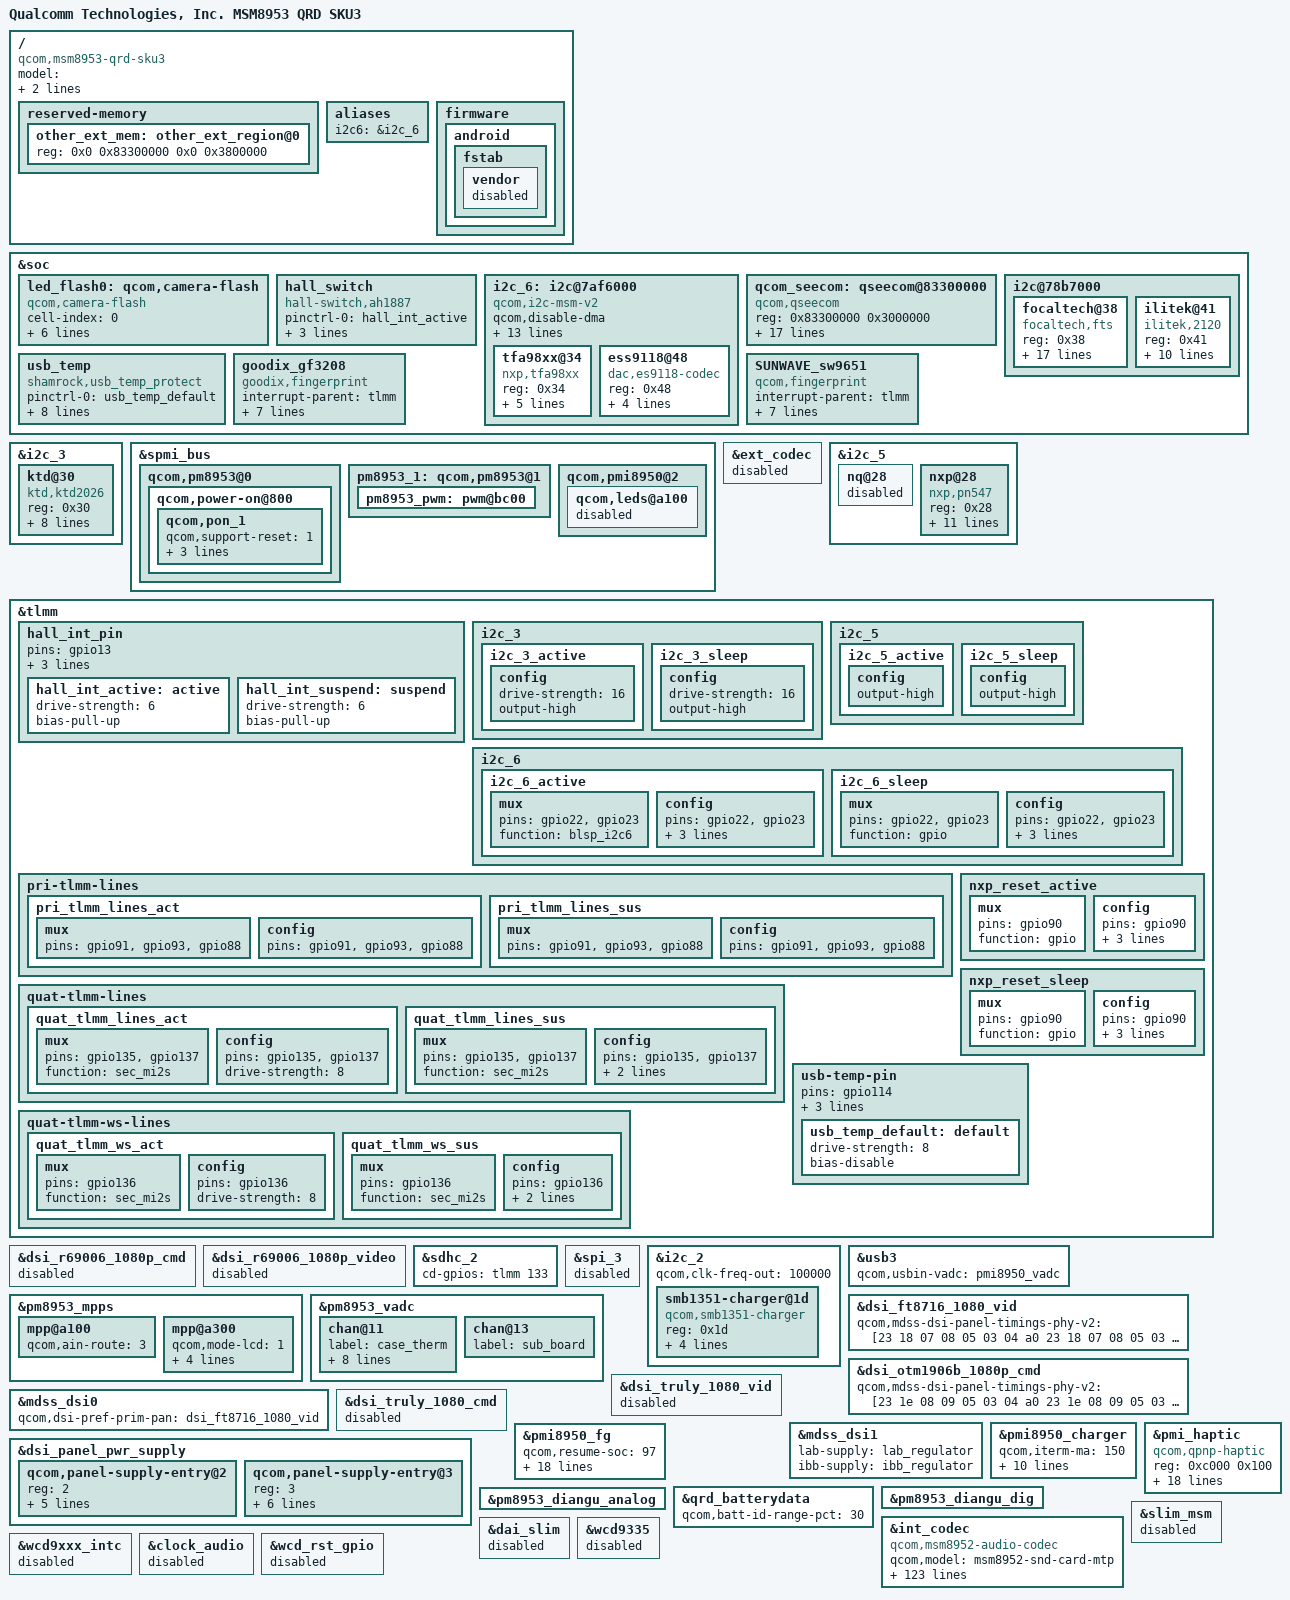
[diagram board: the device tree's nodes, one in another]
/*
 * Copyright (c) 2017, BQ. All rights reserved.
 *
 * This program is free software; you can redistribute it and/or modify
 * it under the terms of the GNU General Public License version 2 and
 * only version 2 as published by the Free Software Foundation.
 *
 * This program is distributed in the hope that it will be useful,
 * but WITHOUT ANY WARRANTY; without even the implied warranty of
 * MERCHANTABILITY or FITNESS FOR A PARTICULAR PURPOSE.  See the
 * GNU General Public License for more details.
 */

/dts-v1/;

#include "msm8953.dtsi"
#include "msm-pmi8950.dtsi"

#include "dsi-panel-ft8716-1080p-video.dtsi"
#include "dsi-panel-otm1906b-1080p-cmd.dtsi"

/ {
	model = "Qualcomm Technologies, Inc. MSM8953 QRD SKU3";
	compatible = "qcom,msm8953-qrd-sku3",
		   "qcom,msm8953-qrd", "qcom,msm8953", "qcom,qrd";
	qcom,board-id= <0x2000b 0>;
};

&soc {
	led_flash0: qcom,camera-flash {
		cell-index = <0>;
		compatible = "qcom,camera-flash";
		qcom,flash-type = <1>;
		qcom,flash-source = <&pmi8950_flash0 &pmi8950_flash1>;
		qcom,torch-source = <&pmi8950_torch0 &pmi8950_torch1>;
		qcom,switch-source = <&pmi8950_switch>;
	};
};

&i2c_3 { /* BLSP1 QUP3 */
    ktd@30 { /* Breath Light-Driven */
        compatible = "ktd,ktd2026";
        reg = <0x30>;
        vdd-supply = <&pm8953_l10>;
        vcc_i2c-supply = <&pm8953_l6>;
        ktd,ledr-parameter_array = <255 12 500 12 500 0 0>;
        ktd,ledg-parameter_array = <255 12 500 12 500 0 0>;
        ktd,ledb-parameter_array = <255 12 500 12 500 0 0>;
    };
};

#include "msm8953-qrd-sku3.dtsi"
#include "bardock-camera.dtsi"

/ {
	reserved-memory {
		other_ext_mem: other_ext_region@0 {
			reg = <0x0 0x83300000 0x0 0x3800000>;
		};
	};

	aliases {
		i2c6  = &i2c_6;
	};
	firmware: firmware {
		android {
			fstab {
				vendor {
					status = "disabled";
				};
			};
		};
	};
};

&spmi_bus {
	qcom,pm8953@0 {
		qcom,power-on@800 {
			qcom,pon_1 {
				qcom,support-reset = <1>;
				qcom,s1-timer = <10256>;
				qcom,s2-timer = <2000>;
				qcom,s2-type = <8>;
			};
		};
	};
	pm8953_1: qcom,pm8953@1 {
		pm8953_pwm: pwm@bc00 {
			status = "okay";
		};
	};
};

&ext_codec {
	status = "disabled";
};

&i2c_5 { /* BLSP2 QUP1 (NFC) */
	nq@28 {
		status = "disabled";
	};
	
    nxp@28 {
            compatible = "nxp,pn547";
            reg = <0x28>;
            qcom,nxp-irq = <&tlmm 17 0x00>;
            qcom,nxp-ven = <&tlmm 16 0x00>;
            qcom,nxp-dw-req = <&tlmm 62 0x00>;
            qcom,nxp-clkreq = <&pm8953_gpios 2 0x00>;
            interrupt-parent = <&tlmm>;
            qcom,clk-src = "BBCLK2";
            interrupts = <17 0>;
            interrupt-names = "nxp-irq";
            pinctrl-names = "nfc_active", "nfc_suspend";
            pinctrl-0 = <&nfc_int_active &nfc_disable_active>;
            pinctrl-1 = <&nfc_int_suspend &nfc_disable_suspend>;
            clocks = <&clock_gcc clk_bb_clk2_pin>;
            clock-names = "ref_clk";
    };
};

&tlmm {
	hall_int_pin {
		pins = "gpio13";
		qcom,pin-func = <0>;
		qcom,num-grp-pins = <1>;
		label = "hall_int_pin";
		hall_int_active: active {
		        drive-strength = <6>;
		        bias-pull-up;
		};
		hall_int_suspend: suspend {
		        drive-strength = <6>;
		        bias-pull-up;
		};
	};

	i2c_3 {
		i2c_3_active: i2c_3_active {
			config {
				drive-strength = <16>;
				output-high;
			};
		};
		i2c_3_sleep: i2c_3_sleep {
			config {
				drive-strength = <16>;
				output-high;
			};
		};
	};

	i2c_5 {
		i2c_5_active: i2c_5_active {
			config {
				output-high;
			};
		};
		i2c_5_sleep: i2c_5_sleep {
			config {
				output-high;
			};
		};
	};

	i2c_6 {
		i2c_6_active: i2c_6_active {
			/* active state */
			mux {
				pins = "gpio22", "gpio23";
				function = "blsp_i2c6";
			};

			config {
				pins = "gpio22", "gpio23";
				drive-strength = <2>;
				bias-disable;
				output-high;
			};
		};

		i2c_6_sleep: i2c_6_sleep {
			/* suspended state */
			mux {
				pins = "gpio22", "gpio23";
				function = "gpio";
			};

			config {
				pins = "gpio22", "gpio23";
				drive-strength = <2>;
				bias-disable;
				output-high;
			};
		};
	};

	pri-tlmm-lines {
		pri_tlmm_lines_act: pri_tlmm_lines_act {
			mux {
				pins = "gpio91", "gpio93", "gpio88";
			};
			config {
				pins = "gpio91", "gpio93", "gpio88";
			};
		};
		pri_tlmm_lines_sus: pri_tlmm_lines_sus {
			mux {
				pins = "gpio91", "gpio93", "gpio88";
			};
			config {
				pins = "gpio91", "gpio93", "gpio88";
			};
		};
	};

	quat-tlmm-lines {
		quat_tlmm_lines_act: quat_tlmm_lines_act {
			mux {
				pins = "gpio135", "gpio137";
				function = "sec_mi2s";
			};

			config {
				pins = "gpio135", "gpio137";
				drive-strength = <8>;
			};
		};

		quat_tlmm_lines_sus: quat_tlmm_lines_sus {
			mux {
				pins = "gpio135", "gpio137";
				function = "sec_mi2s";
			};

			config {
				pins = "gpio135", "gpio137";
				drive-strength = <2>;
				bias-pull-down;
			};
		};
	};

	quat-tlmm-ws-lines {
		quat_tlmm_ws_act: quat_tlmm_ws_act {
			mux {
				pins = "gpio136";
				function = "sec_mi2s";
			};

			config {
				pins = "gpio136";
				drive-strength = <8>;
			};
		};

		quat_tlmm_ws_sus: quat_tlmm_ws_sus {
			mux {
				pins = "gpio136";
				function = "sec_mi2s";
			};

			config {
				pins = "gpio136";
				drive-strength = <2>;
				bias-pull-down;
			};
		};
	};

	nxp_reset_active: nxp_reset_active {
		mux {
			pins = "gpio90";
			function =  "gpio";
		};
		config {
			pins = "gpio90";
			num-grp-pins = <1>;
			drive-strength = <6>;
			bias-pull-up;
		};
	};

	nxp_reset_sleep: nxp_reset_sleep {
			mux {
				pins = "gpio90";
				function =  "gpio";
			};
			config {
				pins = "gpio90";
				num-grp-pins = <1>;
				drive-strength = <2>;
				bias-disable;
			};
	};

	usb-temp-pin {
		pins = "gpio114";
		qcom,num-grp-pins = <1>;
		qcom,pin-func = <0>;
		label = "usb-temp-pin";
		usb_temp_default: default {
			drive-strength = <8>;
			bias-disable;
		};
	};

};

&dsi_r69006_1080p_cmd {
	status = "disabled";
};

&dsi_r69006_1080p_video {
	status = "disabled";
};

&spmi_bus {
	qcom,pmi8950@2 {
		qcom,leds@a100 {
			status = "disabled";
		};
	};
};

&sdhc_2 {
	cd-gpios = <&tlmm 133 0x0>;
};

&spi_3 {
	status = "disabled";
};

&i2c_2 {
	qcom,clk-freq-out = <100000>;
};

&soc {
	hall_switch {
		compatible = "hall-switch,ah1887";
		pinctrl-names = "hall_active","hall_suspend";
		pinctrl-0 = <&hall_int_active>;
		pinctrl-1 = <&hall_int_suspend>;
		vdd-io-supply = <&pm8953_l5>;
		interrupt-names = "hall_irq";
		hall,irq-gpio = <&tlmm 13 0x2008>;
	};

	i2c_6: i2c@7af6000 { /* BLSP2 QUP2 */
		compatible = "qcom,i2c-msm-v2";
		qcom,disable-dma;
		#address-cells = <1>;
		#size-cells = <0>;
		reg-names = "qup_phys_addr";
		reg = <0x7af6000 0x600>;
		interrupt-names = "qup_irq";
		interrupts = <0 300 0>;
		qcom,clk-freq-out = <400000>;
		qcom,clk-freq-in  = <19200000>;
		clock-names = "iface_clk", "core_clk";
		clocks = <&clock_gcc clk_gcc_blsp2_ahb_clk>,
			<&clock_gcc clk_gcc_blsp2_qup2_i2c_apps_clk>;
		pinctrl-names = "i2c_active", "i2c_sleep";
		pinctrl-0 = <&i2c_6_active>;
		pinctrl-1 = <&i2c_6_sleep>;
		qcom,noise-rjct-scl = <0>;
		qcom,noise-rjct-sda = <0>;
		qcom,master-id = <84>;
		dmas = <&dma_blsp2 6 64 0x20000020 0x20>,
			<&dma_blsp2 7 32 0x20000020 0x20>;
		dma-names = "tx", "rx";
	};

	/delete-node/ qseecom@85b00000;

	qcom_seecom: qseecom@83300000 {
		compatible = "qcom,qseecom";
		reg = <0x83300000 0x3000000>;
		reg-names = "secapp-region";
		qcom,hlos-num-ce-hw-instances = <1>;
		qcom,hlos-ce-hw-instance = <0>;
		qcom,qsee-ce-hw-instance = <0>;
		qcom,disk-encrypt-pipe-pair = <2>;
		qcom,support-fde;
		qcom,msm-bus,name = "qseecom-noc";
		qcom,msm-bus,num-cases = <4>;
		qcom,msm-bus,num-paths = <1>;
		qcom,support-bus-scaling;
		qcom,msm-bus,vectors-KBps =
			<55 512 0 0>,
			<55 512 0 0>,
			<55 512 120000 1200000>,
			<55 512 393600 3936000>;
		clocks = <&clock_gcc clk_crypto_clk_src>,
			 <&clock_gcc clk_gcc_crypto_clk>,
			 <&clock_gcc clk_gcc_crypto_ahb_clk>,
			 <&clock_gcc clk_gcc_crypto_axi_clk>;
		clock-names = "core_clk_src", "core_clk",
				"iface_clk", "bus_clk";
		qcom,ce-opp-freq = <100000000>;
	};

	i2c@78b7000 { /* BLSP1 QUP3 */
		status = "okay";
		focaltech@38{
			compatible = "focaltech,fts";
			reg = <0x38>;
			interrupt-parent = <&tlmm>;
			interrupts = <65 0x2>;
			/*vdd_ana-supply = <&vdd_vreg>;*/
			/*vdd-supply = <&pm8953_l10>;*/
			vcc_i2c-supply = <&pm8953_l6>;
			/* pins used by touchscreen */
			pinctrl-names = "pmx_ts_active","pmx_ts_suspend",
							"pmx_ts_release";
			pinctrl-0 = <&ts_int_active &ts_reset_active>;
			pinctrl-1 = <&ts_int_suspend &ts_reset_suspend>;
			pinctrl-2 = <&ts_release>;
			focaltech,name = "fts_ts";
			focaltech,family-id = <0x08>;
			focaltech,reset-gpio = <&tlmm 64 0x1>;
			focaltech,irq-gpio = <&tlmm 65 0x02>;
			focaltech,max-touch-number = <10>;
			focaltech,display-coords = <0 0 1080 1920>;
			focaltech,have-key;
			focaltech,key-number = <3>;
			focaltech,keys = <158 172 139>;
			focaltech,key-y-coord = <2000>;
			focaltech,key-x-coords = <200 600 800>;

		};
	};

	i2c@78b7000 { /* BLSP1 QUP3 */
		status = "ok";
		/*address-cells = <1>;*/
		/*size-cells = <0>;*/
		/*qcom,clk-freq-out = <400000>;*/
		ilitek@41{
			compatible = "ilitek,2120";
			reg = <0x41>;
			interrupt-parent = <&tlmm>;
			interrupts = <65 0x8>;
			ilitek,vci-gpio = <&tlmm 110 0x0>;
			vcc_i2c-supply = <&pm8953_l6>;
			vdd-supply = <&pm8953_l17>;
			ilitek,name = "ilitek_i2c";
			ilitek,reset-gpio = <&tlmm 64 0x00>;
			ilitek,irq-gpio = <&tlmm 65 0x00>;
			ilitek,vbus = "vcc_i2c";
			ilitek,vdd = "vdd";
		};
	};

	usb_temp {
		compatible = "shamrock,usb_temp_protect";
		pinctrl-names = "default";
		pinctrl-0 = <&usb_temp_default>;
		shamrock,gpio_usb_temp_protect = <&tlmm 114 0x00>;
		shamrock,need_protect_temp = <100>;
		shamrock,need_recover_temp = <85>;
		shamrock,open_mosfet_temp = <15>;
		shamrock,close_mosfet_temp = <10>;
		shamrock,interval_switch_temp = <7>;
		vdd-supply = <&pm8953_l6>;
		qcom,usb_temp-vadc = <&pm8953_vadc>;
		status = "okay";
	};

	goodix_gf3208 {
		compatible = "goodix,fingerprint";
		interrupt-parent = <&tlmm>;
		interrupts = <48 0x0>;

		vcc_spi-supply  = <&pm8953_l6>;
		vdd_ana-supply  = <&pm8953_l6>;
		vdd_io-supply   = <&pm8953_l6>;

		fp-gpio-reset = <&tlmm 140 0>;
		fp-gpio-irq = <&tlmm 48 0>;
		goodix,gpio_pwr = <&tlmm 35 0>;
	};

	SUNWAVE_sw9651 {
		compatible = "qcom,fingerprint";
		interrupt-parent = <&tlmm>;
		interrupts = <48 0x0>;

		vcc_spi-supply  = <&pm8953_l6>;
		vdd_ana-supply  = <&pm8953_l6>;
		vdd_io-supply   = <&pm8953_l6>;

		qcom,reset-gpio = <&tlmm 140 0>;
		qcom,irq-gpio = <&tlmm 48 0>;
		qcom,pwr-gpio = <&tlmm 35 0>;
	};
};

&usb3 {
	qcom,usbin-vadc = <&pmi8950_vadc>;
};

&pm8953_mpps {
	mpp@a100 {
		qcom,ain-route = <3>; /* AMUX 8 */
	};
	mpp@a300 {
		/* MPP4 - LCD_PWM config */
		qcom,mode-lcd = <1>; /* AIN input */
		qcom,invert-lcd = <0>;  /* Enable MPP */
		qcom,master-en-lcd = <1>;
		qcom,src-sel-lcd = <5>; /* Function constant */
		qcom,vin-sel-lcd = <2>;
	};
};

&pm8953_vadc {
	chan@11 {
		label = "case_therm";
		reg = <0x11>;
		qcom,decimation = <0>;
		qcom,pre-div-channel-scaling = <0>;
		qcom,calibration-type = "ratiometric";
		qcom,scale-function = <2>;
		qcom,hw-settle-time = <2>;
		qcom,fast-avg-setup = <0>;
		qcom,vadc-thermal-node;
	};
	chan@13 {
		label = "sub_board";
		status = "okay";
	};
};

&dsi_ft8716_1080_vid {
	qcom,mdss-dsi-panel-timings-phy-v2 = [23 18 07 08 05 03 04 a0
		23 18 07 08 05 03 04 a0
		23 18 07 08 05 03 04 a0
		23 18 07 08 05 03 04 a0
		23 1e 07 08 05 03 04 a0];
};

&dsi_otm1906b_1080p_cmd {
	qcom,mdss-dsi-panel-timings-phy-v2 = [23 1e 08 09 05 03 04 a0
		23 1e 08 09 05 03 04 a0
		23 1e 08 09 05 03 04 a0
		23 1e 08 09 05 03 04 a0
		23 1a 08 09 05 03 04 a0];
};

&mdss_dsi0 {
	qcom,dsi-pref-prim-pan = <&dsi_ft8716_1080_vid>;
};

&dsi_truly_1080_vid {
	status = "disabled";
};

&dsi_truly_1080_cmd {
	status = "disabled";
};

&mdss_dsi1 {
	lab-supply = <&lab_regulator>;
	ibb-supply = <&ibb_regulator>;
};

&dsi_panel_pwr_supply {
	qcom,panel-supply-entry@2 {
		reg = <2>;
		qcom,supply-name = "lab";
		qcom,supply-min-voltage = <4600000>;
		qcom,supply-max-voltage = <6000000>;
		qcom,supply-enable-load = <100000>;
		qcom,supply-disable-load = <100>;
	};

	qcom,panel-supply-entry@3 {
		reg = <3>;
		qcom,supply-name = "ibb";
		qcom,supply-min-voltage = <4600000>;
		qcom,supply-max-voltage = <6000000>;
		qcom,supply-enable-load = <100000>;
		qcom,supply-disable-load = <100>;
		qcom,supply-post-on-sleep = <10>;
	};
};

&pmi8950_charger {
	qcom,iterm-ma = <150>;
	qcom,float-voltage-mv = <4400>;
	qcom,resume-delta-mv = <100>;
	qcom,thermal-mitigation = <3000 2500 1950 1400 900 700 0>;
	qcom,fastchg-current-ma = <2200>;
	qcom,charging-timeout-mins = <768>;
	qcom,fastchg-current-comp = <1200>;
	/* 11 for 4.2V, 16 for 4.1V */
	qcom,float-voltage-comp = <16>;
	qcom,report-temp-by-d-work;
	qcom,override-usb-current;
};

&pmi8950_fg {
	qcom,resume-soc = <97>;
	qcom,fg-iterm-ma = <180>;
	qcom,fg-chg-iterm-ma = <150>;
	qcom,fg-cutoff-voltage-mv = <3400>;
	qcom,fg-cc-cv-threshold-mv = <4390>;
	qcom,cycle-counter-low-soc = <15>;
	qcom,cycle-counter-high-soc = <85>;
	qcom,cl-max-temp-decidegc = <450>;
	qcom,cl-min-temp-decidegc = <150>;
	qcom,cl-max-start-soc = <5>;
	qcom,capacity-learning-feedback;
	qcom,cold-bat-decidegc = <0>;
	qcom,cool-bat-decidegc = <150>;
	qcom,warm-bat-decidegc = <450>;
	qcom,fg-delta-soc = <1>;
	qcom,fg-vbat-estimate-diff-mv = <200>;
	qcom,fg-therm-delay-us = <3000>;
	qcom,cold-hot-jeita-hysteresis = <20 20>;
	qcom,ext-sense-type-mp;
};

&qrd_batterydata {
	qcom,batt-id-range-pct = <30>;
	#include "batterydata-qrd-jiade-4v4-3075mah.dtsi"
	#include "batterydata-qrd-feimaotui-4v4-3090mah.dtsi"
	/delete-node/ qcom,qrd_msm8937_sku1_2920mah;
};

&i2c_2 {
	//Parallel-charger configuration
	smb1351-charger@1d {
		compatible = "qcom,smb1351-charger";
		reg = <0x1d>;
		qcom,parallel-en-pin-polarity = <1>;
		qcom,parallel-charger;
		qcom,float-voltage-mv = <4400>;
		qcom,recharge-mv = <100>;
	};
};

&pmi_haptic {
	compatible = "qcom,qpnp-haptic";
	reg = <0xc000 0x100>;
	interrupts = <0x3 0xc0 0x0>,
		<0x3 0xc0 0x1>;
	interrupt-names = "sc-irq", "play-irq";
	qcom,play-mode = "buffer";
	qcom,wave-play-rate-us = <4255>;
	qcom,actuator-type = "lra";
	qcom,wave-shape = "sine";
	qcom,vmax-mv = <2000>;
	qcom,ilim-ma = <90>;
	qcom,sc-deb-cycles = <1>;
	qcom,int-pwm-freq-khz = <505>;
	qcom,brake-pattern = [00 00 00 00];
	qcom,use-play-irq;
	qcom,use-sc-irq;
	qcom,wave-samples = [7e 7e 7e 7e 7e 7e 7e];
	qcom,wave-rep-cnt = <1>;
	qcom,wave-samp-rep-cnt = <1>;
	qcom,lra-auto-res-mode = "none";
	qcom,lra-res-cal-period = <1>;
	qcom,correct-lra-drive-freq;
};

&i2c_6 {
	tfa98xx@34 {
		compatible = "nxp,tfa98xx";
		reg = <0x34>;
		nxp,tfa_max-vol-steps=<0x01>;
		nxp,reset-gpio = <&tlmm 89 0>;
		nxp,irq-gpio = <&tlmm 90 0x2008>;
		pinctrl-names = "nxp_reset_active","nxp_reset_suspend";
		pinctrl-0 = <&nxp_reset_active>;
		pinctrl-1 = <&nxp_reset_sleep>;
		status = "okay";
	};

	ess9118@48 {
		status = "okay";
		compatible = "dac,es9118-codec";
		reg = <0x48>;
		es9118,enable-gpio = <&tlmm 111 0>;
		es9118,power-gpio = <&tlmm 138 0>;
		es9118,cycle-gpio = <&tlmm 44 0>;
		es9118,reset-gpio = <&tlmm 120 0>;
	};
};

&pm8953_diangu_dig {
	status = "ok";
};

&pm8953_diangu_analog {
	status = "ok";
};

&int_codec {
	status = "ok";
	/delete-property/ qcom,cdc-us-euro-gpios;
	/delete-property/ asoc-wsa-codec-names;
	/delete-property/ asoc-wsa-codec-prefixes;
	compatible = "qcom,msm8952-audio-codec";
	qcom,model = "msm8952-snd-card-mtp";
	reg =	<0xc051000 0x4>,
		<0xc051004 0x4>,
		<0xc055000 0x4>,
		<0xc052000 0x4>,
		<0xc054000 0x4>;
	reg-names = "csr_gp_io_mux_mic_ctl",
		"csr_gp_io_mux_spkr_ctl",
		"csr_gp_io_lpaif_pri_pcm_pri_mode_muxsel",
		"csr_gp_io_mux_quin_ctl",
		"csr_gp_io_mux_mic_ext_clk_ctl";

	qcom,msm-hs-micbias-type = "external";//  internal
	qcom,msm-mbhc-hphl-swh = <1>;
	qcom,msm-mbhc-gnd-swh = <0>;   //0

	qcom,audio-routing =
		"RX_BIAS", "MCLK",
		"SPK_RX_BIAS", "MCLK",
		"INT_LDO_H", "MCLK",
		"MIC BIAS External", "Handset Mic",
		"MIC BIAS External2", "Headset Mic",
		"MIC BIAS External", "Secondary Mic",
		"AMIC1", "MIC BIAS External",
		"AMIC2", "MIC BIAS External2",
		"AMIC3", "MIC BIAS External";

	qcom,msm-ext-pa = "quinary","quaternary";
	qcom,msm-mclk-freq = <9600000>;
	qcom,msm-gpios =
		"pri_i2s",
		"us_eu_gpio",
		"quin_i2s",
		"quat_i2s";
	qcom,pinctrl-names =
		"all_off",
		"pri_i2s_act",
		"us_eu_gpio_act",
		"pri_i2s_us_eu_gpio_act",
		"quin_act",
		"quin_pri_i2s_act",
		"quin_us_eu_gpio_act",
		"quin_us_eu_gpio_pri_i2s_act",
		"quat_i2s_act",
		"quat_pri_i2s_act",
		"quat_us_eu_gpio_act",
		"quat_pri_i2s_us_eu_gpio_act",
		"quat_quin_act",
		"quat_quin_pri_i2s_act",
		"quat_quin_us_eu_gpio_act",
		"quat_quin_us_eu_gpio_pri_i2s_act";
	pinctrl-names =
		"all_off",
		"pri_i2s_act",
		"us_eu_gpio_act",
		"pri_i2s_us_eu_gpio_act",
		"quin_act",
		"quin_pri_i2s_act",
		"quin_us_eu_gpio_act",
		"quin_us_eu_gpio_pri_i2s_act",
		"quat_i2s_act",
		"quat_pri_i2s_act",
		"quat_us_eu_gpio_act",
		"quat_pri_i2s_us_eu_gpio_act",
		"quat_quin_act",
		"quat_quin_pri_i2s_act",
		"quat_quin_us_eu_gpio_act",
		"quat_quin_us_eu_gpio_pri_i2s_act";
	pinctrl-0 = <&cdc_pdm_lines_sus
		&quat_tlmm_lines_sus &quat_tlmm_ws_sus
		&cdc_pdm_lines_2_sus &cross_conn_det_sus
		&pri_tlmm_lines_sus &pri_tlmm_ws_sus>;
	pinctrl-1 = <&cdc_pdm_lines_act
		&quat_tlmm_lines_sus &quat_tlmm_ws_sus
		&cdc_pdm_lines_2_act &cross_conn_det_sus
		&pri_tlmm_lines_sus &pri_tlmm_ws_sus>;
	pinctrl-2 = <&cdc_pdm_lines_sus
		&quat_tlmm_lines_sus &quat_tlmm_ws_sus
		&cdc_pdm_lines_2_sus &cross_conn_det_act
		&pri_tlmm_lines_sus &pri_tlmm_ws_sus>;
	pinctrl-3 = <&cdc_pdm_lines_act
		&quat_tlmm_lines_sus &quat_tlmm_ws_sus
		&cdc_pdm_lines_2_act &cross_conn_det_act
		&pri_tlmm_lines_sus &pri_tlmm_ws_sus>;
	pinctrl-4 = <&cdc_pdm_lines_sus
		&quat_tlmm_lines_sus &quat_tlmm_ws_sus
		&cdc_pdm_lines_2_sus &cross_conn_det_sus
		&pri_tlmm_lines_act &pri_tlmm_ws_act>;
	pinctrl-5 = <&cdc_pdm_lines_act
		&quat_tlmm_lines_sus &quat_tlmm_ws_sus
		&cdc_pdm_lines_2_act &cross_conn_det_sus
		&pri_tlmm_lines_act &pri_tlmm_ws_act>;
	pinctrl-6 = <&cdc_pdm_lines_sus
		&quat_tlmm_lines_sus &quat_tlmm_ws_sus
		&cdc_pdm_lines_2_sus &cross_conn_det_act
		&pri_tlmm_lines_act &pri_tlmm_ws_act>;
	pinctrl-7 = <&cdc_pdm_lines_act
		&quat_tlmm_lines_sus &quat_tlmm_ws_sus
		&cdc_pdm_lines_2_act &cross_conn_det_act
		&pri_tlmm_lines_act &pri_tlmm_ws_act>;
	pinctrl-8 = <&cdc_pdm_lines_sus
		&quat_tlmm_lines_act &quat_tlmm_ws_act
		&cdc_pdm_lines_2_sus &cross_conn_det_sus
		&pri_tlmm_lines_sus &pri_tlmm_ws_sus>;
	pinctrl-9 = <&cdc_pdm_lines_act
		&quat_tlmm_lines_act &quat_tlmm_ws_act
		&cdc_pdm_lines_2_act &cross_conn_det_sus
		&pri_tlmm_lines_sus &pri_tlmm_ws_sus>;
	pinctrl-10 = <&cdc_pdm_lines_sus
		&quat_tlmm_lines_act &quat_tlmm_ws_act
		&cdc_pdm_lines_2_sus &cross_conn_det_act
		&pri_tlmm_lines_sus &pri_tlmm_ws_sus>;
	pinctrl-11 = <&cdc_pdm_lines_act
		&quat_tlmm_lines_act &quat_tlmm_ws_act
		&cdc_pdm_lines_2_act &cross_conn_det_act
		&pri_tlmm_lines_sus &pri_tlmm_ws_sus>;
	pinctrl-12 = <&cdc_pdm_lines_sus
		&quat_tlmm_lines_act &quat_tlmm_ws_act
		&cdc_pdm_lines_2_sus &cross_conn_det_sus
		&pri_tlmm_lines_act &pri_tlmm_ws_act>;
	pinctrl-13 = <&cdc_pdm_lines_act
		&quat_tlmm_lines_act &quat_tlmm_ws_act
		&cdc_pdm_lines_2_act &cross_conn_det_sus
		&pri_tlmm_lines_act &pri_tlmm_ws_act>;
	pinctrl-14 = <&cdc_pdm_lines_sus
		&quat_tlmm_lines_act &quat_tlmm_ws_act
		&cdc_pdm_lines_2_sus &cross_conn_det_act
		&pri_tlmm_lines_act &pri_tlmm_ws_act>;
	pinctrl-15 = <&cdc_pdm_lines_act
		&quat_tlmm_lines_act &quat_tlmm_ws_act
		&cdc_pdm_lines_2_act &cross_conn_det_act
		&pri_tlmm_lines_act &pri_tlmm_ws_act>;

	qcom,hdmi-dba-codec-rx;
	asoc-platform = <&pcm0>, <&pcm1>, <&pcm2>, <&voip>, <&voice>,
		<&loopback>, <&compress>, <&hostless>,
		<&afe>, <&lsm>, <&routing>, <&lpa>;
	asoc-platform-names = "msm-pcm-dsp.0", "msm-pcm-dsp.1",
		"msm-pcm-dsp.2", "msm-voip-dsp",
		"msm-pcm-voice", "msm-pcm-loopback",
		"msm-compress-dsp", "msm-pcm-hostless",
		"msm-pcm-afe", "msm-lsm-client",
		"msm-pcm-routing", "msm-pcm-lpa";
	asoc-cpu = <&dai_pri_auxpcm>,
		<&dai_mi2s0>, <&dai_mi2s1>,
		<&dai_mi2s2>, <&dai_mi2s3>,
		<&dai_mi2s5>, <&dai_mi2s6>,
		<&sb_0_rx>, <&sb_0_tx>, <&sb_1_rx>, <&sb_1_tx>,
		<&sb_3_rx>, <&sb_3_tx>, <&sb_4_rx>, <&sb_4_tx>,
		<&bt_sco_rx>, <&bt_sco_tx>,
		<&int_fm_rx>, <&int_fm_tx>,
		<&afe_pcm_rx>, <&afe_pcm_tx>,
		<&afe_proxy_rx>, <&afe_proxy_tx>,
		<&incall_record_rx>, <&incall_record_tx>,
		<&incall_music_rx>, <&incall_music_2_rx>;
	asoc-cpu-names = "msm-dai-q6-auxpcm.1",
		"msm-dai-q6-mi2s.0", "msm-dai-q6-mi2s.1",
		"msm-dai-q6-mi2s.2", "msm-dai-q6-mi2s.3",
		"msm-dai-q6-mi2s.5", "msm-dai-q6-mi2s.6",
		"msm-dai-q6-dev.16384", "msm-dai-q6-dev.16385",
		"msm-dai-q6-dev.16386", "msm-dai-q6-dev.16387",
		"msm-dai-q6-dev.16390", "msm-dai-q6-dev.16391",
		"msm-dai-q6-dev.16392", "msm-dai-q6-dev.16393",
		"msm-dai-q6-dev.12288", "msm-dai-q6-dev.12289",
		"msm-dai-q6-dev.12292", "msm-dai-q6-dev.12293",
		"msm-dai-q6-dev.224", "msm-dai-q6-dev.225",
		"msm-dai-q6-dev.241", "msm-dai-q6-dev.240",
		"msm-dai-q6-dev.32771", "msm-dai-q6-dev.32772",
		"msm-dai-q6-dev.32773", "msm-dai-q6-dev.32770";
};

&slim_msm {
	status = "disabled";
};

&dai_slim {
	status = "disabled";
};

&wcd9xxx_intc {
	status = "disabled";
};

&clock_audio {
	status = "disabled";
};

&wcd9335 {
	status = "disabled";
};

&wcd_rst_gpio {
	status = "disabled";
};
